# ISD91000_v4_2 register map
File version: 1.0
Registers are 32-bit, read-write, reset 0x0 unless marked. A register's access mark holds for its fields unless they carry their own. Offsets are from the block's base; [hi:lo] are bit positions; {n}, {i} and the like mark numbered series.

## INT — INT Register Map
Base 0x50000300
0x00 IRQ0_SRC ro reset not defined — IRQ0 (WDT) Interrupt Source Identity Register
  [2:0] INT_SRC — Interrupt Source Identity. Bit2: 0. Bit1: 0. Bit0: WDT_INT
0x04 IRQ1_SRC ro reset not defined — IRQ1 (DPWM) Interrupt Source Identity Register
  [2:0] INT_SRC — Interrupt Source Identity. Bit2: 0. Bit1: 0. Bit0: DPWM_INT
0x08 IRQ2_SRC ro reset not defined — IRQ2 (ADC) Interrupt Source Identity Register
  [2:0] INT_SRC — Interrupt Source Identity. Bit2: 0. Bit1: 0. Bit0: ADC_INT
0x0C IRQ3_SRC ro reset not defined — Reserved
0x10 IRQ4_SRC ro reset not defined — IRQ4 (SPIM) Interrupt Source Identity Register
  [2:0] INT_SRC — Interrupt Source Identity. Bit2: 0. Bit1: 0. Bit0: SPIM_INT
{0x0+4i} IRQ{i}_SRC ro reset not defined (i=5..7) — IRQ{i} (Timer{i-5}) Interrupt Source Identity Register
  [2:0] INT_SRC — Interrupt Source Identity. Bit2: 0. Bit1: 0. Bit0: Timer{i-5}_INT
0x20 IRQ8_SRC ro reset not defined — IRQ8 (GPA/B) Interrupt Source Identity Register
  [2:0] INT_SRC — Interrupt Source Identity. Bit2: 0. Bit1: GPB_INT. Bit0: GPA_INT
0x24 IRQ9_SRC ro reset not defined — IRQ9 (SPI0) Interrupt Source Identity Register
  [2:0] INT_SRC — Interrupt Source Identity. Bit2: 0. Bit1: 0. Bit0: SPI0_INT
0x28 IRQ10_SRC ro reset not defined — IRQ10 (PWM0) Interrupt Source Identity Register
  [2:0] INT_SRC — Interrupt Source Identity. Bit2: 0. Bit1: 0. Bit0: PWM0_INT
0x2C IRQ11_SRC ro reset not defined — IRQ11 (PDMA) Interrupt Source Identity Register
  [2:0] INT_SRC — Interrupt Source Identity. Bit2: 0. Bit1: 0. Bit0: PDMA_INT
0x30 IRQ12_SRC ro reset not defined — IRQ12 (TimerF) Interrupt Source Identity Register
  [2:0] INT_SRC — Interrupt Source Identity. Bit2: 0. Bit1: 0. Bit0: TimerF_INT
0x34 IRQ13_SRC ro reset not defined — IRQ13 (RTC) Interrupt Source Identity Register
  [2:0] INT_SRC — Interrupt Source Identity. Bit2: 0. Bit1: 0. Bit0: RTC_INT
0x38 IRQ14_SRC ro reset not defined — Reserved
0x3C IRQ15_SRC ro reset not defined — IRQ15 (PWM1) Interrupt Source Identity Register
  [2:0] INT_SRC — Interrupt Source Identity. Bit2: 0. Bit1: 0. Bit0: PWM1_INT
0x40 IRQ16_SRC ro reset not defined — Reserved
0x44 IRQ17_SRC ro reset not defined — IRQ17 (UART0) Interrupt Source Identity Register
  [2:0] INT_SRC — Interrupt Source Identity. Bit2: 0. Bit1: 0. Bit0: UART0_INT
0x48 IRQ18_SRC ro reset not defined — IRQ18 (BOD) Interrupt Source Identity Register
  [2:0] INT_SRC — Interrupt Source Identity. Bit2: 0. Bit1: 0. Bit0: BOD_INT
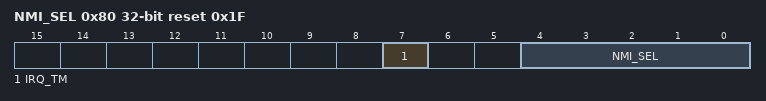
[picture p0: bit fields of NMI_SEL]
0x80 NMI_SEL reset 0x1F — NMI Source Interrupt Select Control Register
  [7] IRQ_TM — IRQ Test Mode. This bit is the protected bit. To program this bit needs an open lock sequence, write "59h", "16h", "88h" to register SYS_REGLCTL to un-lock this bit. Refer to the register SYS_REGLCTL at address SYS_BA+0x100.
    0=The interrupt register MCU_IRQ operates in normal mode. The MCU_IRQ collects all the interrupts from the peripheral and generates interrupt to MCU; 1=All the interrupts from peripheral to MCU are blocked. The peripheral IRQ signals (0-15) are replaced by the value in the MCU_IRQ register
  [4:0] NMI_SEL — NMI Source Interrupt Select. The NMI interrupt to Cortex-M0 can be selected from one of the interrupt [18:0]. The NMI_SEL bit is used to select the NMI interrupt source. Note: IRQ3, IRQ14 and IRQ16 are reserved.
0x84 MCU_IRQ — MCU IRQ Number Identify Register
  [15:0] MCU_IRQ — MCU IRQ Source Test Mode. The MCU_IRQ collects all the interrupts from the peripherals and generates the synchronous interrupt to MCU Cortex-M0. There are two modes to generate interrupt to MCU Cortex-M0, the normal mode and test mode. When MCU_IRQ[n] is "0": Writing MCU_IRQ[n] "1" will generate an interrupt to Cortex_M0 IRQ[n]. When MCU_IRQ[n] is "1" (meaning an interrupt is asserted): Writing MCU_IRQ[n] "1" will clear the interrupt; writing MCU_IRQ[n] "0": has no effect. Note: IRQ3, IRQ14 and IRQ16 are reserved.
